# STM32F101C4T6 register map
File version: 1.0
STM32F101C4T6,STM32F101C6T6,STM32F101C8T6,STM32F101C8U6,STM32F101CBT6,STM32F101CBU6,STM32F101R4T6,STM32F101R6T6,STM32F101R8T6,STM32F101RBH6,STM32F101RBT6,STM32F101RCT6,STM32F101RDT6,STM32F101RET6,STM32F101RFT6,STM32F101RGT6,STM32F101T4U6,STM32F101T6U6,STM32F101T8U6,STM32F101TBU6,STM32F101V8T6,STM32F101VBT6,STM32F101VCT6,STM32F101VDT6,STM32F101VET6,STM32F101VFT6,STM32F101VGT6,STM32F101ZCT6,STM32F101ZDT6,STM32F101ZET6,STM32F101ZFT6,STM32F101ZGT6,STM32F102C4T6,STM32F102C6T6,STM32F102C8T6,STM32F102CBT6,STM32F102R4T6,STM32F102R6T6,STM32F102R8T6,STM32F102RBT6,STM32F103C4T6,STM32F103C6T6,STM32F103C6U6,STM32F103C8T6,STM32F103C8T7,STM32F103CBT6,STM32F103CBT7,STM32F103CBU6,STM32F103CBU7,STM32F103R4H6,STM32F103R4T6,STM32F103R6H6,STM32F103R6T6,STM32F103R8H6,STM32F103R8H7,STM32F103R8T6,STM32F103R8T7,STM32F103RBH6,STM32F103RBH7,STM32F103RBT6,STM32F103RBT7,STM32F103RCT6,STM32F103RCT7,STM32F103RCY6,STM32F103RCY7,STM32F103RDT6,STM32F103RDY6,STM32F103RET6,STM32F103RET7,STM32F103REY6,STM32F103REY7,STM32F103RFT6,STM32F103RFT7,STM32F103RGT6,STM32F103RGT7,STM32F103T4U6,STM32F103T6U6,STM32F103T8U6,STM32F103T8U7,STM32F103TBU6,STM32F103TBU7,STM32F103V8H6,STM32F103V8T6,STM32F103VBH6,STM32F103VBH7,STM32F103VBI6,STM32F103VBI7,STM32F103VBT6,STM32F103VBT7,STM32F103VCH6,STM32F103VCH7,STM32F103VCT6,STM32F103VCT7,STM32F103VDH6,STM32F103VDH7,STM32F103VDT6,STM32F103VDT7,STM32F103VEH6,STM32F103VEH7,STM32F103VET6,STM32F103VET7,STM32F103VFT6,STM32F103VFT7,STM32F103VGT6,STM32F103VGT7,STM32F103ZCH6,STM32F103ZCH7,ST
Registers are 32-bit, access not given, reset 0x0 unless marked. A register's access mark holds for its fields unless they carry their own. Offsets are from the block's base; lines under a group give offsets from that group; [hi:lo] are bit positions; {n}, {i} and the like mark numbered series; 'fields as' and 'values as' point back to an identical list; <NAME> marks a mode.

## Memory map
0x40000000 TIM2
0x40000400 TIM3
0x40000800 TIM4
0x40000C00 TIM5
0x40001000 TIM6
0x40001400 TIM7
0x40001800 TIM12
0x40001C00 TIM13
0x40002000 TIM14
0x40002800 RTC
0x40002C00 WWDG
0x40003000 IWDG
0x40003800 SPI2
0x40003C00 SPI3
0x40004400 USART2
0x40004800 USART3
0x40004C00 UART4
0x40005000 UART5
0x40005400 I2C1
0x40005800 I2C2
0x40005C00 USBFS
0x40006400 CAN1
0x40006800 CAN2
0x40006C00 BKP
0x40007000 PWR
0x40007400 DAC
0x40010000 AFIO
0x40010400 EXTI
0x40010800 GPIOA
0x40010C00 GPIOB
0x40011000 GPIOC
0x40011400 GPIOD
0x40011800 GPIOE
0x40011C00 GPIOF
0x40012000 GPIOG
0x40012400 ADC1
0x40012800 ADC2
0x40012C00 TIM1
0x40013000 SPI1
0x40013400 TIM8
0x40013800 USART1
0x40013C00 ADC3
0x40014C00 TIM9
0x40015000 TIM10
0x40015400 TIM11
0x40018000 SDIO
0x40020000 DMA1
0x40020400 DMA2
0x40021000 RCC
0x40023000 CRC
0x40028000 ETH
0x50000000 USB_OTG_FS
0xA0000000 FSMC

## TIM2
Base 0x40000000
Same registers: TIM3 0x40000400, TIM4 0x40000800, TIM5 0x40000C00
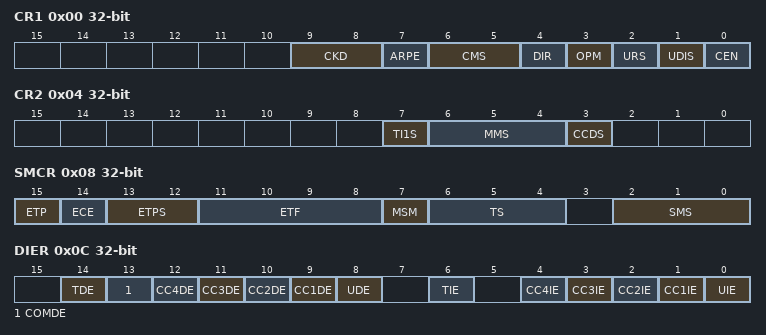
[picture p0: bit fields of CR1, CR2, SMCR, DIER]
0x00 CR1
  [9:8] CKD, [7] ARPE, [6:5] CMS, [4] DIR, [3] OPM, [2] URS, [1] UDIS, [0] CEN
0x04 CR2
  [7] TI1S, [6:4] MMS, [3] CCDS
0x08 SMCR
  [15] ETP, [14] ECE, [13:12] ETPS, [11:8] ETF, [7] MSM, [6:4] TS, [2:0] SMS
0x0C DIER
  [14] TDE, [13] COMDE, [n+8] CC{n}DE (n=1..4), [8] UDE, [6] TIE, [n] CC{n}IE (n=1..4), [0] UIE
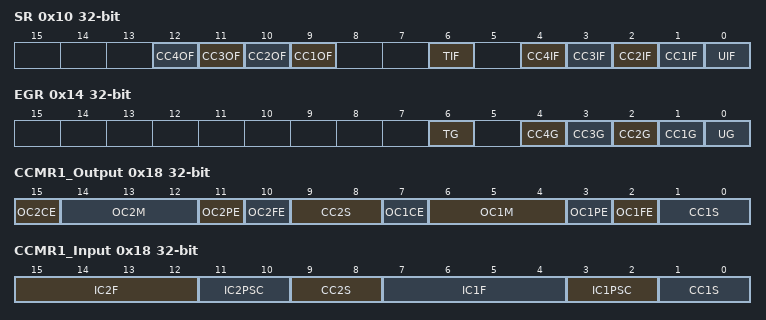
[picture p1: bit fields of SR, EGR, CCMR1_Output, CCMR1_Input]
0x10 SR
  [n+8] CC{n}OF (n=1..4), [6] TIF, [n] CC{n}IF (n=1..4), [0] UIF
0x14 EGR
  [6] TG, [n] CC{n}G (n=1..4), [0] UG
0x18 CCMR1_Output
  [15] OC2CE, [14:12] OC2M, [11] OC2PE, [10] OC2FE, [9:8] CC2S, [7] OC1CE, [6:4] OC1M, [3] OC1PE, [2] OC1FE, [1:0] CC1S
0x18 CCMR1_Input
  [15:12] IC2F, [11:10] IC2PSC, [9:8] CC2S, [7:4] IC1F, [3:2] IC1PSC, [1:0] CC1S
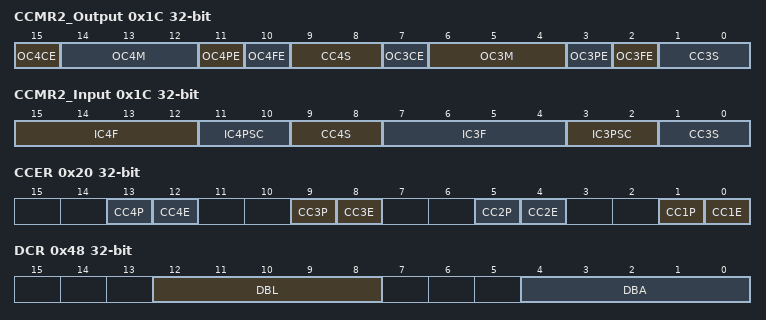
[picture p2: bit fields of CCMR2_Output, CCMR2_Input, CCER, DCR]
0x1C CCMR2_Output
  [15] OC4CE, [14:12] OC4M, [11] OC4PE, [10] OC4FE, [9:8] CC4S, [7] OC3CE, [6:4] OC3M, [3] OC3PE, [2] OC3FE, [1:0] CC3S
0x1C CCMR2_Input
  [15:12] IC4F, [11:10] IC4PSC, [9:8] CC4S, [7:4] IC3F, [3:2] IC3PSC, [1:0] CC3S
0x20 CCER
  [4n-3] CC{n}P (n=1..4), [4n-4] CC{n}E (n=1..4)
0x24 CNT
  [15:0] CNT
0x28 PSC
  [15:0] PSC
0x2C ARR
  [15:0] ARR
{0x30+4i} CCR{i} (i=1..4)
  [15:0] CCR{i}
0x48 DCR
  [12:8] DBL, [4:0] DBA
0x4C DMAR
  [15:0] DMAB

## TIM1
Base 0x40012C00
Same registers: TIM8 0x40013400
Registers as TIM2; these are added or differ:
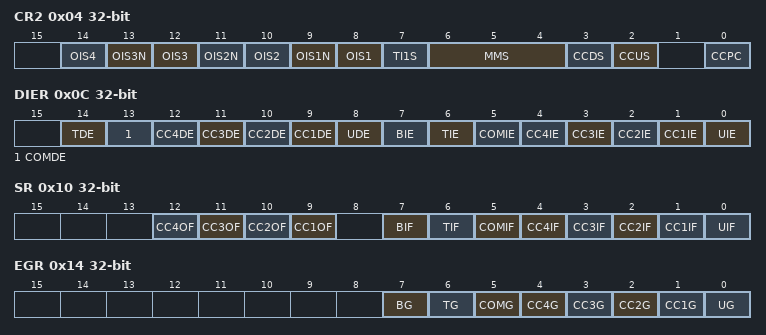
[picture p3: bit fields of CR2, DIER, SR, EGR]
0x04 CR2
  [2n+6] OIS{n} (n=1..4), [13] OIS3N, [11] OIS2N, [9] OIS1N, [7] TI1S, [6:4] MMS, [3] CCDS, [2] CCUS, [0] CCPC
0x0C DIER
  [14] TDE, [13] COMDE, [n+8] CC{n}DE (n=1..4), [8] UDE, [7] BIE, [6] TIE, [5] COMIE, [n] CC{n}IE (n=1..4), [0] UIE
0x10 SR
  [n+8] CC{n}OF (n=1..4), [7] BIF, [6] TIF, [5] COMIF, [n] CC{n}IF (n=1..4), [0] UIF
0x14 EGR
  [7] BG, [6] TG, [5] COMG, [n] CC{n}G (n=1..4), [0] UG
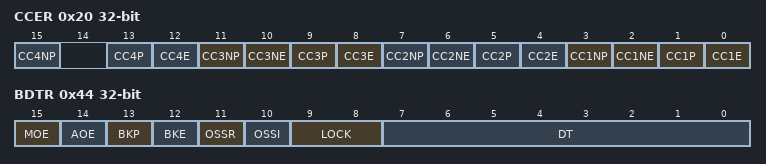
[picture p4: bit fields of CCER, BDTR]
0x20 CCER
  [4n-1] CC{n}NP (n=1..4), [4n-3] CC{n}P (n=1..4), [4n-4] CC{n}E (n=1..4), [10] CC3NE, [6] CC2NE, [2] CC1NE
0x30 RCR
  [7:0] REP
0x44 BDTR
  [15] MOE, [14] AOE, [13] BKP, [12] BKE, [11] OSSR, [10] OSSI, [9:8] LOCK, [7:0] DT
0x4C DMAR
  [31:0] DMAB
